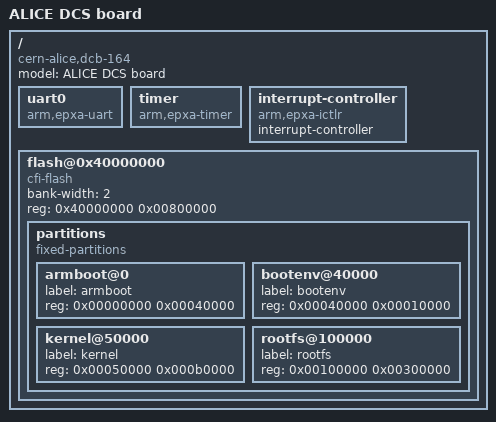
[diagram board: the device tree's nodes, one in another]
/dts-v1/;

/ {
    model = "ALICE DCS board";
    compatible = "cern-alice,dcb-164";

    #address-cells = <1>;
    #size-cells = <1>;

    uart0 {
        compatible = "arm,epxa-uart";
    };

    timer {
        compatible = "arm,epxa-timer";
    };

    interrupt-controller {
        compatible = "arm,epxa-ictlr";
	interrupt-controller;
    };

    flash@0x40000000 {
        compatible = "cfi-flash";
        #address-cells = <1>;
	#size-cells = <1>;
	bank-width = <2>;
	reg = <0x40000000 0x00800000>;

	partitions {
	    compatible = "fixed-partitions";
	    #address-cells = <1>;
	    #size-cells = <1>;

    	    armboot@0 {
	        label = "armboot";
	        reg = <0x00000000 0x00040000>;
 	    };

	     bootenv@40000 {
	        label = "bootenv";
	        reg = <0x00040000 0x00010000>;
	     };

	    kernel@50000 {
	        label = "kernel";
	        reg = <0x00050000 0x000b0000>;
	    };

	    rootfs@100000 {
	        label = "rootfs";
	        reg = <0x00100000 0x00300000>;
	    };
	};
    };

//    osc: oscillator {
//        #clock-cells = <1>;
//	clock-output-names = "clka", "clkb";
//    };
//
//    soc {
//        #address-cells = <1>;
// 	#size-cells = <1>;
// 	compatible = "simple-bus";
// 	ranges = <0 0x7fffc000 0x8000000>;
//    };
//
//    cpus {
//        #address-cells = <1>;
//	#size-cells = <0>;
//
//	cpu@0 {
//	    device_type = "cpu";
//	    reg = <0x0>;
//	    compatible = "arm,arm922t";
//	};
//    };
//
//    ebi@12000000 {
//        compatible = "arm,external-bus-interface";
//        reg = <0x12000000 0x100>;
//    };
// 
//    serial@f00 {
//        compatible = "vendor,some-uart";
//        reg = <0xf00 0x10>;
//    };
//
//    chosen {
//        stdout-path = "/serial@f00:57600";
//    };

    // wdt

// I2C, GPIO, SCSN, ...
};
